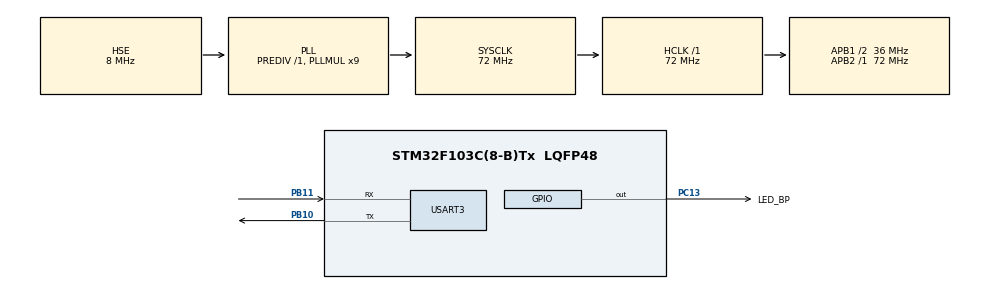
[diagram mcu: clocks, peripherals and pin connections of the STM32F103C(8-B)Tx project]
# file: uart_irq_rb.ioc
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Mcu.Family=STM32F1
NVIC.USART3_IRQn=true\:0\:0\:false\:false\:true\:true\:true
RCC.PLLSourceVirtual=RCC_PLLSOURCE_HSE
PC15-OSC32_OUT.Mode=LSE-External-Oscillator
PD1-OSC_OUT.Mode=HSE-External-Oscillator
PB10.Mode=Asynchronous
PC13-TAMPER-RTC.Signal=GPIO_Output
PD0-OSC_IN.Signal=RCC_OSC_IN
RCC.APB1CLKDivider=RCC_HCLK_DIV2
PC14-OSC32_IN.Signal=RCC_OSC32_IN
PB11.Signal=USART3_RX
RCC.SYSCLKSource=RCC_SYSCLKSOURCE_PLLCLK
ProjectManager.StackSize=0x400
PD1-OSC_OUT.Signal=RCC_OSC_OUT
PA13.Signal=SYS_JTMS-SWDIO
PB11.Mode=Asynchronous
ProjectManager.TargetToolchain=STM32CubeIDE
RCC.HCLKFreq_Value=72000000
RCC.APB2TimFreq_Value=72000000
RCC.USBFreq_Value=72000000
PC15-OSC32_OUT.Signal=RCC_OSC32_OUT
RCC.AHBFreq_Value=72000000
PB10.Signal=USART3_TX
PD0-OSC_IN.Mode=HSE-External-Oscillator
board=custom
RCC.PLLMUL=RCC_PLL_MUL9
PC13-TAMPER-RTC.GPIO_Label=LED_BP
RCC.APB2Freq_Value=72000000
PC13-TAMPER-RTC.PinState=GPIO_PIN_SET
PC14-OSC32_IN.Mode=LSE-External-Oscillator
PA14.Mode=Serial_Wire
PA13.Mode=Serial_Wire
Mcu.Name=STM32F103C(8-B)Tx
RCC.SYSCLKFreq_VALUE=72000000
Mcu.Package=LQFP48
USART3.VirtualMode=VM_ASYNC
PA14.Signal=SYS_JTCK-SWCLK
ProjectManager.HeapSize=0x200
NVIC.PriorityGroup=NVIC_PRIORITYGROUP_4
RCC.APB1TimFreq_Value=72000000
RCC.APB1Freq_Value=36000000

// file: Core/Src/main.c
/* USER CODE BEGIN Header */
/**
 ******************************************************************************
 * @file           : main.c
 * @brief          : Main program body
 ******************************************************************************
 * @attention
 *
 * <h2><center>&copy; Copyright (c) 2021 STMicroelectronics.
 * All rights reserved.</center></h2>
 *
 * This software component is licensed by ST under BSD 3-Clause license,
 * the "License"; You may not use this file except in compliance with the
 * License. You may obtain a copy of the License at:
 *                        opensource.org/licenses/BSD-3-Clause
 *
 ******************************************************************************
 */
/* USER CODE END Header */
#include "main.h"

/* USER CODE BEGIN Includes */
#include "uart_rb.h"
/* USER CODE END Includes */

/* USER CODE BEGIN PD */
#define RX_BUF_LEN    3  /*!< Rx buffer size in bytes */
#define UART_RB_SIZE  64 /*!< Ring buffer size in bytes, must be a power of 2 */
/* USER CODE END PD */

UART_HandleTypeDef huart3;

void SystemClock_Config(void);
static void MX_GPIO_Init(void);
static void MX_USART3_UART_Init(void);

int main(void)
{
	/* USER CODE BEGIN 1 */
	uint8_t rx_buf[RX_BUF_LEN] = {0};
	uint8_t tx_rb_buf[UART_RB_SIZE] = {0}, rx_rb_buf[UART_RB_SIZE] = {0};
	uint8_t rx_bytes;

	/* USER CODE END 1 */

	/* MCU Configuration--------------------------------------------------------*/

	/* Reset of all peripherals, Initializes the Flash interface and the Systick. */
	HAL_Init();

	/* Configure the system clock */
	SystemClock_Config();

	/* Initialize all configured peripherals */
	MX_GPIO_Init();
	MX_USART3_UART_Init();

	/* Infinite loop */
	/* USER CODE BEGIN WHILE */

	/* Initialize the Tx and Rx ring buffers for UART3 */
	uart_rb_init(&huart3, tx_rb_buf, rx_rb_buf, UART_RB_SIZE);

	while (1)
	{
		rx_bytes = uart_rb_rxGetCount(&huart3);

		if (rx_bytes > 0) {
			rx_bytes = uart_rb_read(&huart3, rx_buf, RX_BUF_LEN);

			if (rx_buf[0] == '1') {
				HAL_GPIO_WritePin(LED_BP_GPIO_Port, LED_BP_Pin, GPIO_PIN_RESET);
				uart_rb_write(&huart3, (uint8_t *)"Led on!\r\n", 9);
			}
			else if (rx_buf[0] == '0') {
				HAL_GPIO_WritePin(LED_BP_GPIO_Port, LED_BP_Pin, GPIO_PIN_SET);
				uart_rb_write(&huart3, (uint8_t *)"Led off!\r\n", 10);
			}
		}

		__WFI();

		/* USER CODE END WHILE */

	}
}

void SystemClock_Config(void)
{
	RCC_OscInitTypeDef RCC_OscInitStruct = {0};
	RCC_ClkInitTypeDef RCC_ClkInitStruct = {0};

	/** Initializes the RCC Oscillators according to the specified parameters
	 * in the RCC_OscInitTypeDef structure.
	 */
	RCC_OscInitStruct.OscillatorType = RCC_OSCILLATORTYPE_HSE;
	RCC_OscInitStruct.HSEState = RCC_HSE_ON;
	RCC_OscInitStruct.HSEPredivValue = RCC_HSE_PREDIV_DIV1;
	RCC_OscInitStruct.HSIState = RCC_HSI_ON;
	RCC_OscInitStruct.PLL.PLLState = RCC_PLL_ON;
	RCC_OscInitStruct.PLL.PLLSource = RCC_PLLSOURCE_HSE;
	RCC_OscInitStruct.PLL.PLLMUL = RCC_PLL_MUL9;
	if (HAL_RCC_OscConfig(&RCC_OscInitStruct) != HAL_OK)
	{
		Error_Handler();
	}
	/** Initializes the CPU, AHB and APB buses clocks
	 */
	RCC_ClkInitStruct.ClockType = RCC_CLOCKTYPE_HCLK|RCC_CLOCKTYPE_SYSCLK
			|RCC_CLOCKTYPE_PCLK1|RCC_CLOCKTYPE_PCLK2;
	RCC_ClkInitStruct.SYSCLKSource = RCC_SYSCLKSOURCE_PLLCLK;
	RCC_ClkInitStruct.AHBCLKDivider = RCC_SYSCLK_DIV1;
	RCC_ClkInitStruct.APB1CLKDivider = RCC_HCLK_DIV2;
	RCC_ClkInitStruct.APB2CLKDivider = RCC_HCLK_DIV1;

	if (HAL_RCC_ClockConfig(&RCC_ClkInitStruct, FLASH_LATENCY_2) != HAL_OK)
	{
		Error_Handler();
	}
}

static void MX_USART3_UART_Init(void)
{

	huart3.Instance = USART3;
	huart3.Init.BaudRate = 115200;
	huart3.Init.WordLength = UART_WORDLENGTH_8B;
	huart3.Init.StopBits = UART_STOPBITS_1;
	huart3.Init.Parity = UART_PARITY_NONE;
	huart3.Init.Mode = UART_MODE_TX_RX;
	huart3.Init.HwFlowCtl = UART_HWCONTROL_NONE;
	huart3.Init.OverSampling = UART_OVERSAMPLING_16;
	if (HAL_UART_Init(&huart3) != HAL_OK)
	{
		Error_Handler();
	}

}

static void MX_GPIO_Init(void)
{
	GPIO_InitTypeDef GPIO_InitStruct = {0};

	/* GPIO Ports Clock Enable */
	__HAL_RCC_GPIOC_CLK_ENABLE();
	__HAL_RCC_GPIOD_CLK_ENABLE();
	__HAL_RCC_GPIOB_CLK_ENABLE();
	__HAL_RCC_GPIOA_CLK_ENABLE();

	/*Configure GPIO pin Output Level */
	HAL_GPIO_WritePin(LED_BP_GPIO_Port, LED_BP_Pin, GPIO_PIN_SET);

	/*Configure GPIO pin : LED_BP_Pin */
	GPIO_InitStruct.Pin = LED_BP_Pin;
	GPIO_InitStruct.Mode = GPIO_MODE_OUTPUT_PP;
	GPIO_InitStruct.Pull = GPIO_NOPULL;
	GPIO_InitStruct.Speed = GPIO_SPEED_FREQ_LOW;
	HAL_GPIO_Init(LED_BP_GPIO_Port, &GPIO_InitStruct);

}

void Error_Handler(void)
{
	__disable_irq();
	while (1)
	{
	}
}

/************************ (C) COPYRIGHT STMicroelectronics *****END OF FILE****/
